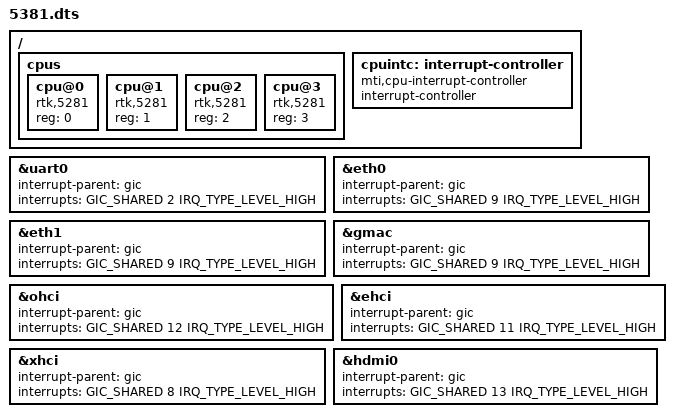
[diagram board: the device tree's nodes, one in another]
/*
 * Realtek Semiconductor Corp.
 *
 * Device Tree Structure
 *
 * Tony Wu (tonywu@realtek.com)
 */

/dts-v1/;

#include <dt-bindings/interrupt-controller/mips-gic.h>
#include "sheipa.dtsi"

/ {
	#address-cells = <1>;
	#size-cells = <1>;

	cpus {
		#address-cells = <1>;
		#size-cells = <0>;

		cpu@0 {
			compatible = "rtk,5281";
			device_type = "cpu";
			reg = <0>;
		};

		cpu@1 {
			compatible = "rtk,5281";
			device_type = "cpu";
			reg = <1>;
		};

		cpu@2 {
			compatible = "rtk,5281";
			device_type = "cpu";
			reg = <2>;
		};

		cpu@3 {
			compatible = "rtk,5281";
			device_type = "cpu";
			reg = <3>;
		};
	};

	cpuintc: interrupt-controller {
		#address-cells = <0>;
		#interrupt-cells = <1>;
		interrupt-controller;
		compatible = "mti,cpu-interrupt-controller";
	};

};

&uart0 {
	interrupt-parent = <&gic>;
	interrupts = <GIC_SHARED 2 IRQ_TYPE_LEVEL_HIGH>;
};

&eth0 {
	interrupt-parent = <&gic>;
	interrupts = <GIC_SHARED 9 IRQ_TYPE_LEVEL_HIGH>;
};

&eth1 {
	interrupt-parent = <&gic>;
	interrupts = <GIC_SHARED 9 IRQ_TYPE_LEVEL_HIGH>;
};

&gmac {
	interrupt-parent = <&gic>;
	interrupts = <GIC_SHARED 9 IRQ_TYPE_LEVEL_HIGH>;
};

&ohci {
	interrupt-parent = <&gic>;
	interrupts = <GIC_SHARED 12 IRQ_TYPE_LEVEL_HIGH>;
};

&ehci {
	interrupt-parent = <&gic>;
	interrupts = <GIC_SHARED 11 IRQ_TYPE_LEVEL_HIGH>;
};

&xhci {
	interrupt-parent = <&gic>;
	interrupts = <GIC_SHARED 8 IRQ_TYPE_LEVEL_HIGH>;
};

&hdmi0 {
	interrupt-parent = <&gic>;
	interrupts = <GIC_SHARED 13 IRQ_TYPE_LEVEL_HIGH>;
};
